# Generic_ARMv8MMainline register map
Vendor: ARM Ltd.; Series: ARMv8-M Mainline architecture (Cortex-M33 / Cortex-M35P / Cortex-M55 / Cortex-M85); File version: 1.0
CPU: CM33 r0p0, little endian, no MPU, no FPU, VTOR, 3 interrupt priority bits
Registers are 32-bit, read-write, reset 0x0 unless marked. A register's access mark holds for its fields unless they carry their own. Offsets are from the block's base; [hi:lo] are bit positions.

## SCnSCB — System Control and ID Registers not in the SCB address range: ICTR (Interrupt Controller Type Register), ACTLR (Auxiliary Control Register), and CPPWR (Coprocessor Power Control -- new in ARMv8-M Mainline). Verified against CMSIS_6 core_cm33.h. Absent entirely on ARMv8-M Baseline, same as ARMv6-M.
Base 0xE000E000
0x04 ICTR ro — Interrupt Controller Type Register
  [3:0] INTLINESNUM — (Number of 32-interrupt NVIC banks implemented) - 1: total external interrupts = (INTLINESNUM+1)*32
0x08 ACTLR — Auxiliary Control Register -- wholly IMPLEMENTATION DEFINED by the architecture, same as on ARMv7-M -- deliberately left with no fields.
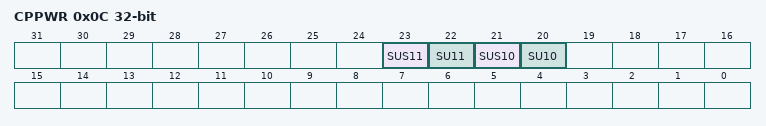
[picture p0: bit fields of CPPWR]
0x0C CPPWR — Coprocessor Power Control Register -- new in ARMv8-M Mainline; only meaningful if an FPU (coprocessors 10/11) is implemented.
  [23] SUS11 — Coprocessor 11 (FPU) power enable in Sleep -- only meaningful if an FPU is implemented
  [22] SU11 — Coprocessor 11 (FPU) power enable -- only meaningful if an FPU is implemented
  [21] SUS10 — Coprocessor 10 (FPU) power enable in Sleep -- only meaningful if an FPU is implemented
  [20] SU10 — Coprocessor 10 (FPU) power enable -- only meaningful if an FPU is implemented

## SysTick — SysTick Timer. Identical register set on every Cortex-M core (ARMv6-M through current ARMv8-M).
Base 0xE000E010
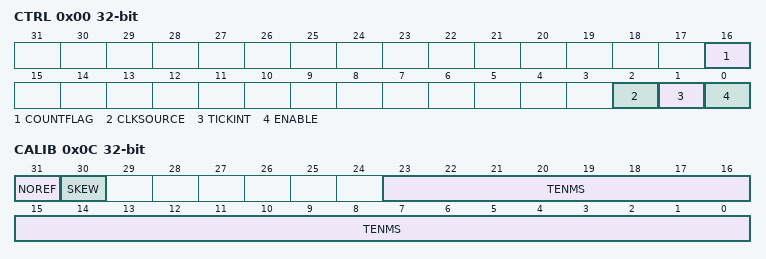
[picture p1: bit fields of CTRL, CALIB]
0x00 CTRL — SysTick Control and Status Register
  [16] COUNTFLAG ro, [2] CLKSOURCE, [1] TICKINT, [0] ENABLE
0x04 LOAD — SysTick Reload Value Register
  [23:0] RELOAD
0x08 VAL — SysTick Current Value Register. Any write clears it to 0 and clears COUNTFLAG.
  [23:0] CURRENT
0x0C CALIB ro — SysTick Calibration Value Register
  [31] NOREF, [30] SKEW, [23:0] TENMS

## DCB — Debug Control Block -- CMSIS's ARMv8-M name for what core_cm0.h/core_cm3.h call CoreDebug (same base address, 0xE000EDF0). Adds DAUTHCTRL (Debug Authentication Control) and DSCSR (Debug Security Control and Status) versus ARMv6-M/ARMv7-M's CoreDebug -- both Security-Extension-related, present regardless of profile. Verified against CMSIS_6 core_cm23.h/core_cm33.h.
Base 0xE000EDF0
0x00 DHCSR — Debug Halting Control and Status Register
  [26] S_RESTART_ST ro — New in ARMv8-M
  [25] S_RESET_ST ro
  [24] S_RETIRE_ST ro
  [20] S_SDE ro — Secure Debug Enabled -- Security Extension only
  [19] S_LOCKUP ro
  [18] S_SLEEP ro
  [17] S_HALT ro
  [16] S_REGRDY ro
  [31:16] DBGKEY wo — Write 0xA05F to enable write access to bits [15:0]; reads as 0
  [5] C_SNAPSTALL
  [3] C_MASKINTS
  [2] C_STEP
  [1] C_HALT
  [0] C_DEBUGEN
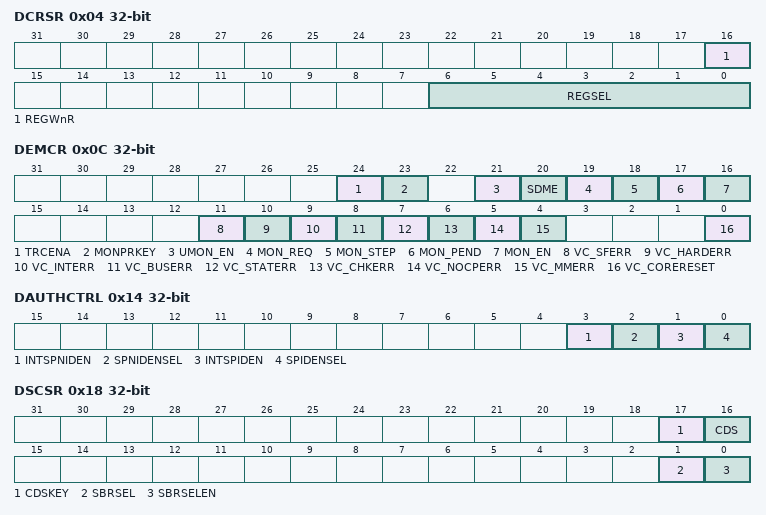
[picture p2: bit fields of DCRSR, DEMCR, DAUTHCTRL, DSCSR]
0x04 DCRSR wo — Debug Core Register Selector Register
  [16] REGWnR, [6:0] REGSEL
0x08 DCRDR — Debug Core Register Data Register
  [31:0] DBGTMP
0x0C DEMCR — Debug Exception and Monitor Control Register
  [24] TRCENA — Trace enable (DWT/ITM/ETM/TPIU) -- only meaningful where those blocks exist
  [23] MONPRKEY — Monitor Pend Request Key
  [21] UMON_EN — Unprivileged Monitor Enable
  [20] SDME — Secure DebugMonitor Enable -- Security Extension only
  [19] MON_REQ — Debug Monitor request
  [18] MON_STEP — Debug Monitor step
  [17] MON_PEND — Debug Monitor pend
  [16] MON_EN — Debug Monitor enable
  [11] VC_SFERR — Debug trap on SecureFault exception -- Security Extension only
  [10] VC_HARDERR — Debug trap on HardFault exception
  [9] VC_INTERR — Debug trap on interrupt/exception service errors
  [8] VC_BUSERR — Debug trap on BusFault exception
  [7] VC_STATERR — Debug trap on UsageFault state error
  [6] VC_CHKERR — Debug trap on UsageFault caused by checking error
  [5] VC_NOCPERR — Debug trap on UsageFault caused by no coprocessor
  [4] VC_MMERR — Debug trap on MemManage exception
  [0] VC_CORERESET — Reset Vector Catch
0x14 DAUTHCTRL — Debug Authentication Control Register -- Security Extension only
  [3] INTSPNIDEN — Internal Secure non-invasive debug enable
  [2] SPNIDENSEL — Secure non-invasive debug enable select
  [1] INTSPIDEN — Internal Secure invasive debug enable
  [0] SPIDENSEL — Secure invasive debug enable select
0x18 DSCSR — Debug Security Control and Status Register -- Security Extension only
  [17] CDSKEY wo — CDS write-enable key
  [16] CDS ro — Current Domain Secure
  [1] SBRSEL — Secure banked register select
  [0] SBRSELEN — Secure banked register select enable
